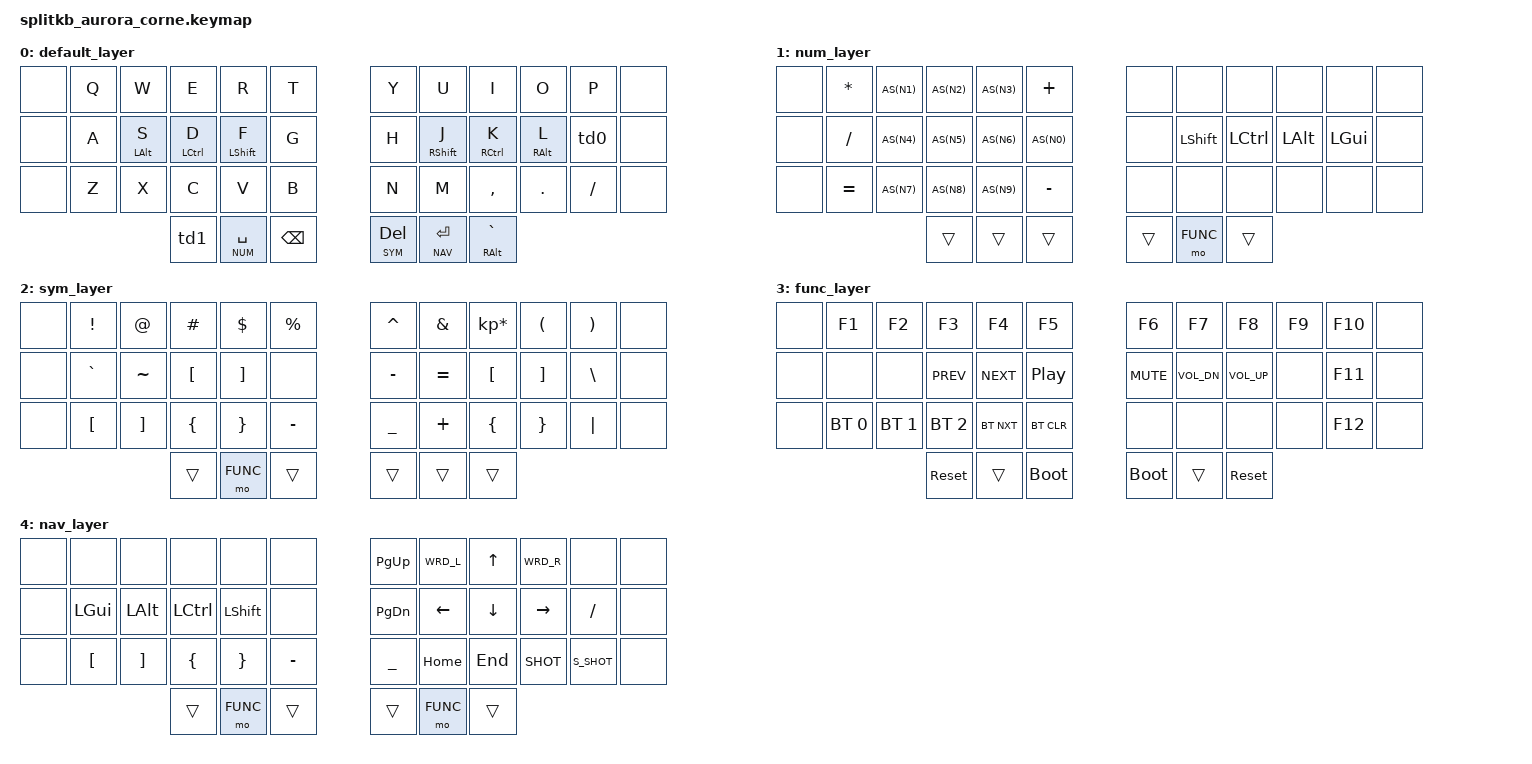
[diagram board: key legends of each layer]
/*
 * Copyright (c) 2020 The ZMK Contributors
 *
 * SPDX-License-Identifier: MIT
 */

#include <dt-bindings/zmk/keys.h>
#include <dt-bindings/zmk/bt.h>
#include <dt-bindings/zmk/ext_power.h>
#include <behaviors.dtsi>

// LAYERS
#define DEFAULT 0
#define NUM     1
#define SYM     2
#define FUNC    3
#define NAV     4

// MACROS
#define SUPER LC(LSHIFT)
#define SUPER2 LA(LC(LSHIFT))
#define AS(keycode) &as LS(keycode) keycode     // Autoshift Macro

// KEYS
#define WRD_L LA(LEFT)
#define WRD_R LA(RIGHT)
#define S_SHOT LG(LS(N4))
#define C_SHOT LG(LS(LC(N4)))

&mt {
  tapping-term-ms = <200>;
  flavor = "tap-preferred";
};

/ {
  behaviors {
    hm: homerow_mods {
      compatible = "zmk,behavior-hold-tap";
      label = "HOMEROW_MODS";
      #binding-cells = <2>;
      tapping-term-ms = <100>;
      quick-tap-ms = <0>;
      require-prior-idle-ms = <150>;
      flavor = "balanced";
      bindings = <&kp>, <&kp>;
    };

    as: auto_shift {
      compatible = "zmk,behavior-hold-tap";
      #binding-cells = <2>;
      tapping_term_ms = <135>;
      quick_tap_ms = <0>;
      flavor = "tap-preferred";
      bindings = <&kp>, <&kp>;
    };

    td0: tap_dance_0 {
      compatible = "zmk,behavior-tap-dance";
      label = "TAP_DANCE_0";
      #binding-cells = <0>;
      tapping-term-ms = <200>;
      bindings = <&kp SQT>, <&kp SEMI>;
    };

    td1: tap_dance_1 {
      compatible = "zmk,behavior-tap-dance";
      label = "TAP_DANCE_1";
      #binding-cells = <0>;
      tapping-term-ms = <200>;
      bindings = <&mt LGUI TAB>, <&kp ESC>;
    };
  };

  combos {
    compatible = "zmk,combos";
    combo_cword {
      timeout-ms = <50>;
      key-positions = <16 19>;
      bindings = <&caps_word>;
    };

    combo_vimwq {
      timeout-ms = <50>;
      key-positions = <1 2>;
      bindings = <&vim_quit>;
    };
  };

  macros {
        vim_quit: vim_quit {
            label = "ZM_vim_quit";
            compatible = "zmk,behavior-macro";
            #binding-cells = <0>;
            bindings
                = <&macro_tap &kp ESC &kp COLON &kp W &kp Q>;
        };
    };

  keymap {
    compatible = "zmk,keymap";

    default_layer {
      bindings = <

&none   /**/  &kp Q           &kp W       &kp E        &kp R    &kp T   /**/  &kp Y    &kp U           &kp I       &kp O       &kp P          /**/  &none
&none   /**/  &kp A      &hm LALT S  &hm LCTRL D  &hm LSHIFT F  &kp G   /**/  &kp H    &hm RSHIFT J    &hm RCTRL K &hm RALT L  &td0           /**/  &none
&none   /**/  &kp Z           &kp X       &kp C       &kp V    &kp B   /**/  &kp N    &kp M           &kp COMMA   &kp DOT     &kp FSLH       /**/  &none
                                        &td1  &lt NUM SPACE    &kp BSPC   /**/  &lt SYM DEL  &lt NAV RET &mt RALT GRAVE

      >;
    };

    num_layer {
      bindings = <

&none   /**/  &kp STAR   AS(N1)  AS(N2)  AS(N3)  &kp PLUS   /**/  &none  &none       &none      &none     &none     /**/  &none
&none   /**/  &kp SLASH  AS(N4)  AS(N5)  AS(N6)  AS(N0)    /**/  &none  &kp LSHIFT  &kp LCTRL  &kp LALT  &kp LGUI  /**/  &none
&none   /**/  &kp EQUAL  AS(N7)  AS(N8)  AS(N9)  &kp MINUS  /**/  &none  &none       &none      &none     &none     /**/  &none
                                     &trans  &trans  &trans  /**/  &trans  &mo FUNC  &trans

      >;
    };

    sym_layer {
      bindings = <

&none   /**/  &kp EXCL    &kp AT      &kp HASH   &kp DLLR    &kp PRCNT   /**/  &kp CARET &kp AMPS  &kp KP_MULTIPLY &kp LPAR &kp RPAR  /**/  &none
&none   /**/  &kp GRAVE   &kp TILDE   &kp LBKT   &kp RBKT    &none       /**/  &kp MINUS &kp EQUAL &kp LBKT        &kp RBKT &kp BSLH  /**/  &none
&none   /**/  &kp LBKT    &kp RBKT    &kp LBRC   &kp RBRC    &kp MINUS   /**/  &kp UNDER &kp PLUS  &kp LBRC        &kp RBRC &kp PIPE  /**/  &none
                                                 &trans &mo FUNC &trans  /**/  &trans &trans &trans

      >;
    };

    func_layer {
      bindings = <

&none   /**/  &kp F1          &kp F2          &kp F3          &kp F4     &kp F5            /**/  &kp F6          &kp F7       &kp F8       &kp F9   &kp F10  /**/  &none
&none   /**/  &none           &none           &kp C_PREV      &kp C_NEXT &kp C_PLAY_PAUSE  /**/  &kp C_MUTE      &kp C_VOL_DN &kp C_VOL_UP &none    &kp F11  /**/  &none
&none   /**/  &bt BT_SEL 0    &bt BT_SEL 1    &bt BT_SEL 2    &bt BT_NXT &bt BT_CLR        /**/  &none           &none        &none        &none    &kp F12  /**/  &none
              &sys_reset &trans &bootloader  /**/  &bootloader &trans &sys_reset

      >;
    };

    nav_layer {
      bindings = <
&none   /**/  &none     &none      &none       &none        &none      /**/  &kp PG_UP  &kp WRD_L  &kp UP    &kp WRD_R  &none       /**/  &none
&none   /**/  &kp LGUI  &kp LALT   &kp LCTRL   &kp LSHIFT   &none      /**/  &kp PG_DN  &kp LEFT   &kp DOWN  &kp RIGHT  &kp SLASH   /**/  &none
&none   /**/  &kp LBKT  &kp RBKT   &kp LBRC    &kp RBRC     &kp MINUS  /**/  &kp UNDER  &kp HOME   &kp END   &kp C_SHOT &kp S_SHOT  /**/  &none
        &trans  &mo FUNC  &trans  /**/  &trans  &mo FUNC  &trans

     >;
  };

  };
};
